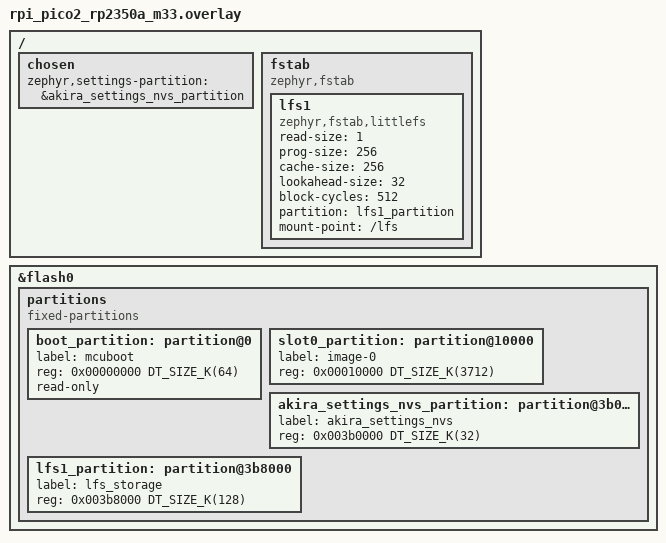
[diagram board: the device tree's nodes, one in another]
/*
 * Raspberry Pi Pico 2 (RP2350) DTS overlay for AkiraOS
 * Board: rpi_pico2
 *
 * RP2350 has 4 MB external QSPI Flash (W25Q32JV on standard Pico 2).
 * Partition layout:
 *   64 KB  — MCUBoot (optional)
 *   2 MB   — Application slot-0
 *   32 KB  — AkiraOS NVS settings
 *   128 KB — LittleFS WASM app storage
 */

/ {
    chosen {
        zephyr,settings-partition = &akira_settings_nvs_partition;
    };

    fstab {
        compatible = "zephyr,fstab";

        lfs1: lfs1 {
            compatible = "zephyr,fstab,littlefs";
            read-size = <1>;
            prog-size = <256>;
            cache-size = <256>;
            lookahead-size = <32>;
            block-cycles = <512>;
            partition = <&lfs1_partition>;
            mount-point = "/lfs";
        };
    };
};

&flash0 {
    partitions {
        compatible = "fixed-partitions";
        #address-cells = <1>;
        #size-cells = <1>;

        boot_partition: partition@0 {
            label = "mcuboot";
            reg = <0x00000000 DT_SIZE_K(64)>;
            read-only;
        };

        slot0_partition: partition@10000 {
            label = "image-0";
            reg = <0x00010000 DT_SIZE_K(3712)>;
        };

        akira_settings_nvs_partition: partition@3b0000 {
            label = "akira_settings_nvs";
            reg = <0x003b0000 DT_SIZE_K(32)>;
        };

        lfs1_partition: partition@3b8000 {
            label = "lfs_storage";
            reg = <0x003b8000 DT_SIZE_K(128)>;
        };
    };
};
